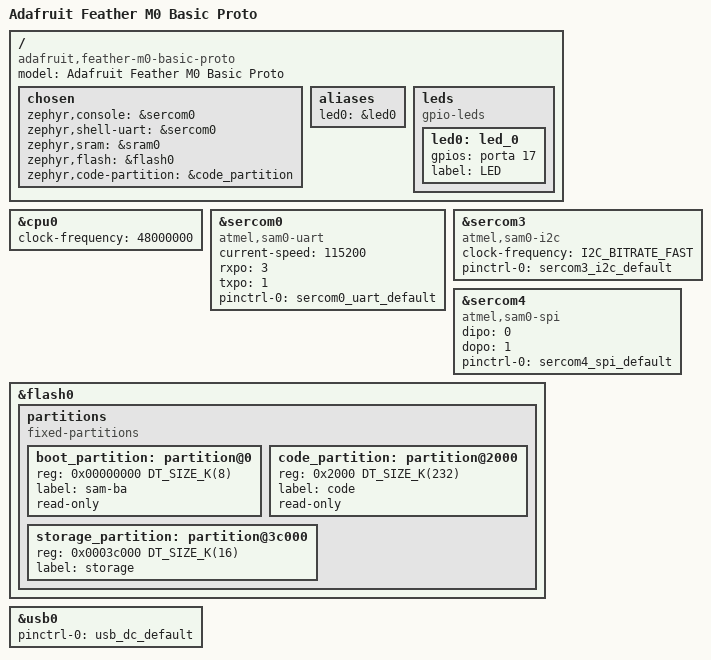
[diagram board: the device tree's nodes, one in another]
/*
 * Copyright (c) 2018 Henrik Brix Andersen <henrik@brixandersen.dk>
 *
 * SPDX-License-Identifier: Apache-2.0
 */

/dts-v1/;
#include <atmel/samd21.dtsi>
#include <atmel/samx2xx18.dtsi>
#include "adafruit_feather_m0_basic_proto-pinctrl.dtsi"
#include "feather_connector.dtsi"

/ {
	compatible = "adafruit,feather-m0-basic-proto", "atmel,samd21g18a",
		     "atmel,samd21";
	model = "Adafruit Feather M0 Basic Proto";

	chosen {
		zephyr,console = &sercom0;
		zephyr,shell-uart = &sercom0;
		zephyr,sram = &sram0;
		zephyr,flash = &flash0;
		zephyr,code-partition = &code_partition;
	};

	/* These aliases are provided for compatibility with samples */
	aliases {
		led0 = &led0;
	};

	leds {
		compatible = "gpio-leds";

		led0: led_0 {
			gpios = <&porta 17 0>;
			label = "LED";
		};
	};
};

&cpu0 {
	clock-frequency = <48000000>;
};

&sercom0 {
	compatible = "atmel,sam0-uart";
	current-speed = <115200>;
	rxpo = <3>;
	txpo = <1>;

	pinctrl-0 = <&sercom0_uart_default>;
	pinctrl-names = "default";
	status = "okay";
};

&sercom3 {
	compatible = "atmel,sam0-i2c";
	clock-frequency = <I2C_BITRATE_FAST>;
	#address-cells = <1>;
	#size-cells = <0>;

	pinctrl-0 = <&sercom3_i2c_default>;
	pinctrl-names = "default";
	status = "okay";
};

&sercom4 {
	compatible = "atmel,sam0-spi";
	#address-cells = <1>;
	#size-cells = <0>;
	dipo = <0>;
	dopo = <1>;

	pinctrl-0 = <&sercom4_spi_default>;
	pinctrl-names = "default";
	status = "okay";
};

&flash0 {
	partitions {
		compatible = "fixed-partitions";
		#address-cells = <1>;
		#size-cells = <1>;

		boot_partition: partition@0 {
			reg = <0x00000000 DT_SIZE_K(8)>;
			label = "sam-ba";
			read-only;
		};

		code_partition: partition@2000 {
			reg = <0x2000 DT_SIZE_K(232)>;
			label = "code";
			read-only;
		};

		/*
		 * The final 16 KiB is reserved for the application.
		 * Storage partition will be used by FCB/LittleFS/NVS
		 * if enabled.
		 */
		storage_partition: partition@3c000 {
			reg = <0x0003c000 DT_SIZE_K(16)>;
			label = "storage";
		};
	};
};

zephyr_udc0: &usb0 {
	pinctrl-0 = <&usb_dc_default>;
	pinctrl-names = "default";
	status = "okay";
};
